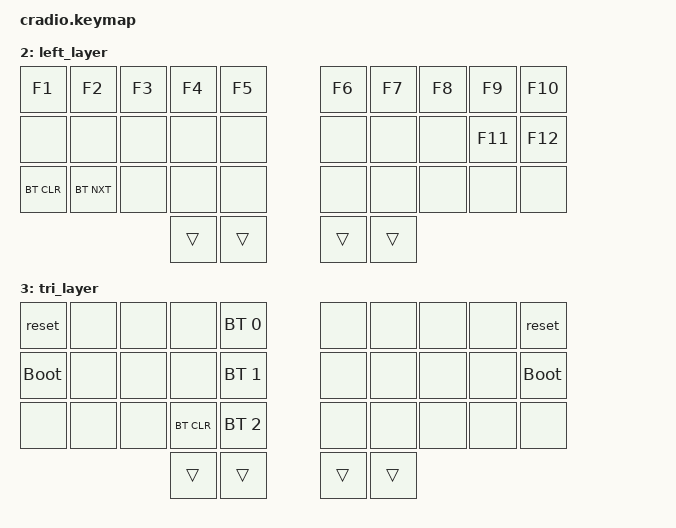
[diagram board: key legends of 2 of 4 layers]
// Copyright (c) 2022 The ZMK Contributors
// SPDX-License-Identifier: MIT

#include <behaviors.dtsi>
#include <dt-bindings/zmk/keys.h>
#include <dt-bindings/zmk/bt.h>

// Home row mods macro
#define HRML(k1,k2,k3,k4) &ht LSHFT k1  &ht LCTRL k2  &ht LALT k3  &ht LGUI k4
#define HRMR(k1,k2,k3,k4) &ht RGUI k1  &ht RALT k2  &ht RCTRL k3  &ht RSHFT k4
#define HYPER(k1) &ht LS(LC(LA(LGUI))) k1

/ {
    behaviors {
        ht: hold_tap {
            label = "hold_tap";
            compatible = "zmk,behavior-hold-tap";
            #binding-cells = <2>;
            flavor = "tap-preferred";
            tapping-term-ms = <220>;
            quick-tap-ms = <150>;
            global-quick-tap;
            bindings = <&kp>, <&kp>;
        };
    };

    conditional_layers {
        compatible = "zmk,conditional-layers";
        tri_layer {
            if-layers = <1 2>;
            then-layer = <3>;
        };
    };

    keymap {
        compatible = "zmk,keymap";
        default_layer {
            bindings = <
        //╭──────────┬──────────┬──────────┬──────────┬──────────╮   ╭──────────┬──────────┬──────────┬──────────┬──────────╮
        //│  Q       │  W       │  E       │  R       │  T       │   │  Y       │  U       │  I       │  O       │  P       │
           HYPER(Q)   &kp W      &kp E      &kp R      &kp T          &kp Y      &kp U      &kp I      &kp O      &kp P
        //├──────────┼──────────┼──────────┼──────────┼──────────┤   ├──────────┼──────────┼──────────┼──────────┼──────────┤
        //│  A       │  S       │  D       │  F       │  G       │   │  H       │  J       │  K       │  L       │     ; :  │
           HRML(A,      S,         D,         F)       &kp G          &kp H      HRMR(J,      K,         L,       SEMICOLON)
        //├──────────┼──────────┼──────────┼──────────┼──────────┤   ├──────────┼──────────┼──────────┼──────────┼──────────┤
        //│  Z       │  X       │  C       │  V       │  B       │   │  N       │  M       │ , <      │ . >      │ / ?      │
           &kp Z      &kp X      &kp C      &kp V      &kp B          &kp N      &kp M      &kp COMMA  &kp DOT    &kp FSLH
        //╰──────────┴──────────┴──────────┼──────────┼──────────┤   ├──────────┼──────────┼──────────┴──────────┴──────────╯
                                            &kp TAB    &lt 1 SPACE   &lt 1 ENTER &lt 2 BSPC
        //                                 ╰──────────┴──────────╯   ╰──────────┴──────────╯
            >;
        };

        right_layer {
            bindings = <
        //╭──────────┬──────────┬──────────┬──────────┬──────────╮   ╭──────────┬──────────┬──────────┬──────────┬──────────╮
        //│   1 !    │   2 @    │   3 #    │   4 $    │   5 %    │   │   6 ^    │   7 &    │   8 *    │   9 (    │  0 )     │
           &kp N1     &kp N2     &kp N3     &kp N4     &kp N5         &kp N6     &kp N7     &kp N8     &kp N9     &kp N0
        //├──────────┼──────────┼──────────┼──────────┼──────────┤   ├──────────┼──────────┼──────────┼──────────┼──────────┤
        //│ LEFT     │  DOWN    │ UP       │ RIGHT    │   ESC    │   │          │   ' "    │  [ {     │   ] }    │    ; :   │
           HRML(LEFT,   DOWN,     UP,        RIGHT)  &kp ESC        &none      HRMR(APOS,    LBKT,       RBKT,    SEMICOLON)
        //├──────────┼──────────┼──────────┼──────────┼──────────┤   ├──────────┼──────────┼──────────┼──────────┼──────────┤
        //│          │          │          │          │          │   │          │    ` ~   │    - _   │    = +   │   \ |    │
           &none      &none      &none      &none      &none          &none      &kp GRAVE  &kp MINUS  &kp EQUAL  &kp BSLH
        //╰──────────┴──────────┴──────────┼──────────┼──────────┤   ├──────────┼──────────┼──────────┴──────────┴──────────╯
                                            &trans     &trans         &trans     &trans
        //                                 ╰──────────┴──────────╯   ╰──────────┴──────────╯
            >;
        };

        left_layer {
            bindings = <
        //╭──────────┬──────────┬──────────┬──────────┬──────────╮   ╭──────────┬──────────┬──────────┬──────────┬──────────╮
        //│    F1    │    F2    │    F3    │    F4    │    F5    │   │    F6    │    F7    │    F8    │    F9    │    F10   │
           &kp F1     &kp F2     &kp F3     &kp F4     &kp F5         &kp F6     &kp F7     &kp F8     &kp F9     &kp F10
        //├──────────┼──────────┼──────────┼──────────┼──────────┤   ├──────────┼──────────┼──────────┼──────────┼──────────┤
        //│          │          │          │          │          │   │          │          │          │    F11   │    F12   │
           &none      &none      &none      &none      &none          &none      &none      &none      &kp F11    &kp F12
        //├──────────┼──────────┼──────────┼──────────┼──────────┤   ├──────────┼──────────┼──────────┼──────────┼──────────┤
        //│ CLEAR BT │  BT NEXT │          │          │          │   │          │          │          │          │          │
           &bt BT_CLR &bt BT_NXT &none      &none      &none          &none      &none      &none      &none      &none
        //╰──────────┴──────────┴──────────┼──────────┼──────────┤   ├──────────┼──────────┼──────────┴──────────┴──────────╯
                                            &trans     &trans         &trans     &trans
        //                                 ╰──────────┴──────────╯   ╰──────────┴──────────╯
            >;
        };

        tri_layer {
            bindings = <
        //╭──────────┬──────────┬──────────┬──────────┬──────────╮   ╭──────────┬──────────┬──────────┬──────────┬──────────╮
        //│ RESET    │          │          │          │PROFILE 0 │   │          │          │          │          │  RESET   │
            &reset     &none      &none      &none     &bt BT_SEL 0    &none      &none      &none      &none       &reset
        //├──────────┼──────────┼──────────┼──────────┼──────────┤   ├──────────┼──────────┼──────────┼──────────┼──────────┤
        //│BOOTLOADER│          │          │          │PROFILE 1 │   │          │          │          │          │BOOTLOADER│
          &bootloader  &none      &none      &none     &bt BT_SEL 1    &none      &none      &none      &none     &bootloader
        //├──────────┼──────────┼──────────┼──────────┼──────────┤   ├──────────┼──────────┼──────────┼──────────┼──────────┤
        //│          │          │          │ CLEAR BT │PROFILE 2 │   │          │          │          │          │          │
            &none      &none      &none     &bt BT_CLR &bt BT_SEL 2    &none      &none      &none      &none      &none
        //╰──────────┴──────────┴──────────┼──────────┼──────────┤   ├──────────┼──────────┼──────────┴──────────┴──────────╯
                                             &trans     &trans         &trans     &trans
        //                                 ╰──────────┴──────────╯   ╰──────────┴──────────╯
            >;
        };
    };
};
